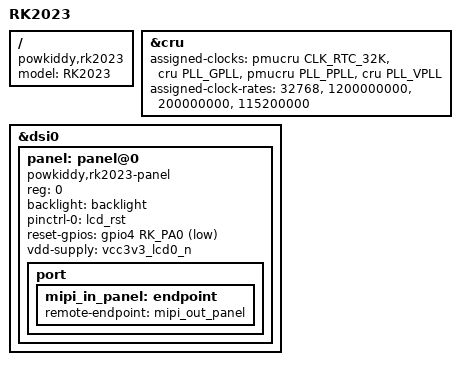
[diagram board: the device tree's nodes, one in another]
// SPDX-License-Identifier: (GPL-2.0+ OR MIT)

/dts-v1/;

#include <dt-bindings/gpio/gpio.h>
#include <dt-bindings/input/linux-event-codes.h>
#include <dt-bindings/pinctrl/rockchip.h>
#include "rk3566-powkiddy-rk2023.dtsi"

/ {
	model = "RK2023";
	compatible = "powkiddy,rk2023", "rockchip,rk3566";
};

&cru {
	assigned-clocks = <&pmucru CLK_RTC_32K>, <&cru PLL_GPLL>,
			  <&pmucru PLL_PPLL>, <&cru PLL_VPLL>;
	assigned-clock-rates = <32768>, <1200000000>,
			  <200000000>, <115200000>;
};

&dsi0 {
	panel: panel@0 {
		compatible = "powkiddy,rk2023-panel", "newvision,nv3051d";
		reg = <0>;
		backlight = <&backlight>;
		pinctrl-names = "default";
		pinctrl-0 = <&lcd_rst>;
		reset-gpios = <&gpio4 RK_PA0 GPIO_ACTIVE_LOW>;
		vdd-supply = <&vcc3v3_lcd0_n>;

		port {
			mipi_in_panel: endpoint {
				remote-endpoint = <&mipi_out_panel>;
			};
		};
	};
};
